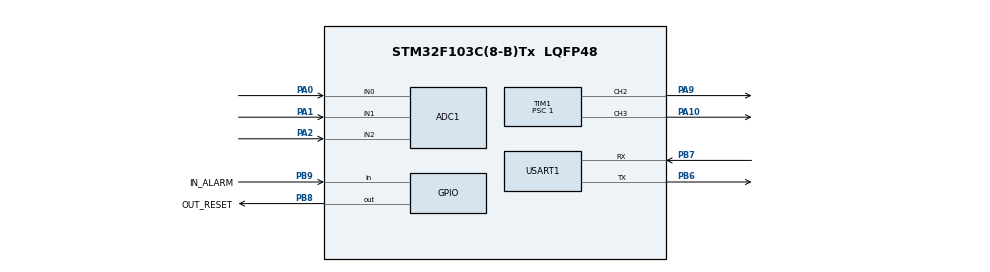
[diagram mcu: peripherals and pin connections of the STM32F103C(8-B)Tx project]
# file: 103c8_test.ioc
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ADC1.Channel-0\#ChannelRegularConversion=ADC_CHANNEL_0
ADC1.Channel-1\#ChannelRegularConversion=ADC_CHANNEL_1
ADC1.Channel-2\#ChannelRegularConversion=ADC_CHANNEL_2
ADC1.ContinuousConvMode=ENABLE
ADC1.DataAlign=ADC_DATAALIGN_RIGHT
ADC1.DiscontinuousConvMode=DISABLE
ADC1.EnableAnalogWatchDog=false
ADC1.EnableRegularConversion=ENABLE
ADC1.ExternalTrigConv=ADC_SOFTWARE_START
ADC1.InjNumberOfConversion=0
ADC1.NbrOfConversion=3
ADC1.NbrOfConversionFlag=1
ADC1.Rank-0\#ChannelRegularConversion=1
ADC1.Rank-1\#ChannelRegularConversion=2
ADC1.Rank-2\#ChannelRegularConversion=3
ADC1.SamplingTime-0\#ChannelRegularConversion=ADC_SAMPLETIME_239CYCLES_5
ADC1.SamplingTime-1\#ChannelRegularConversion=ADC_SAMPLETIME_239CYCLES_5
ADC1.SamplingTime-2\#ChannelRegularConversion=ADC_SAMPLETIME_239CYCLES_5
ADC1.ScanConvMode=ADC_SCAN_ENABLE
ADC1.master=1
Dma.ADC1.1.Direction=DMA_PERIPH_TO_MEMORY
Dma.ADC1.1.Instance=DMA1_Channel1
Dma.ADC1.1.MemDataAlignment=DMA_MDATAALIGN_WORD
Dma.ADC1.1.MemInc=DMA_MINC_ENABLE
Dma.ADC1.1.Mode=DMA_CIRCULAR
Dma.ADC1.1.PeriphDataAlignment=DMA_PDATAALIGN_WORD
Dma.ADC1.1.PeriphInc=DMA_PINC_DISABLE
Dma.ADC1.1.Priority=DMA_PRIORITY_LOW
Dma.Request0=USART1_RX
Dma.Request1=ADC1
Dma.USART1_RX.0.Direction=DMA_PERIPH_TO_MEMORY
Dma.USART1_RX.0.Instance=DMA1_Channel5
Dma.USART1_RX.0.MemDataAlignment=DMA_MDATAALIGN_BYTE
Dma.USART1_RX.0.MemInc=DMA_MINC_ENABLE
Dma.USART1_RX.0.Mode=DMA_NORMAL
Dma.USART1_RX.0.PeriphDataAlignment=DMA_PDATAALIGN_BYTE
Dma.USART1_RX.0.PeriphInc=DMA_PINC_DISABLE
Dma.USART1_RX.0.Priority=DMA_PRIORITY_LOW
Mcu.Family=STM32F1
Mcu.Name=STM32F103C(8-B)Tx
Mcu.Package=LQFP48
NVIC.ADC1_2_IRQn=true\:0\:0\:false\:false\:true\:true
NVIC.DMA1_Channel1_IRQn=true\:0\:0\:false\:false\:true\:false
NVIC.DMA1_Channel5_IRQn=true\:0\:0\:false\:false\:true\:false
NVIC.PriorityGroup=NVIC_PRIORITYGROUP_4
NVIC.USART1_IRQn=true\:0\:0\:false\:false\:true\:true
PA0-WKUP.Signal=ADCx_IN0
PA1.Signal=ADCx_IN1
PA10.Signal=S_TIM1_CH3
PA13.Mode=Serial_Wire
PA13.Signal=SYS_JTMS-SWDIO
PA14.Mode=Serial_Wire
PA14.Signal=SYS_JTCK-SWCLK
PA2.Signal=ADCx_IN2
PA9.Signal=S_TIM1_CH2
PB6.Mode=Asynchronous
PB6.Signal=USART1_TX
PB7.Mode=Asynchronous
PB7.Signal=USART1_RX
PB8.GPIO_Label=OUT_RESET
PB8.Signal=GPIO_Output
PB9.GPIO_Label=IN_ALARM
PB9.Signal=GPIO_Input
ProjectManager.HeapSize=0x200
ProjectManager.StackSize=0x400
ProjectManager.TargetToolchain=TrueSTUDIO
RCC.APB1Freq_Value=8000000
RCC.APB2Freq_Value=8000000
SH.ADCx_IN0.0=ADC1_IN0,IN0
SH.ADCx_IN1.0=ADC1_IN1,IN1
SH.ADCx_IN2.0=ADC1_IN2,IN2
SH.S_TIM1_CH2.0=TIM1_CH2,PWM Generation2 CH2
SH.S_TIM1_CH3.0=TIM1_CH3,PWM Generation3 CH3
TIM1.Channel-PWM\ Generation2\ CH2=TIM_CHANNEL_2
TIM1.Channel-PWM\ Generation3\ CH3=TIM_CHANNEL_3
TIM1.Period=399
TIM1.Prescaler=1
USART1.VirtualMode=VM_ASYNC
VP_TIM1_VS_ClockSourceINT.Mode=Internal
board=custom

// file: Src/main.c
/**
  ******************************************************************************
  * @file           : main.c
  * @brief          : Main program body
  ******************************************************************************
  ** This notice applies to any and all portions of this file
  * that are not between comment pairs USER CODE BEGIN and
  * USER CODE END. Other portions of this file, whether
  * inserted by the user or by software development tools
  * are owned by their respective copyright owners.
  *
  * COPYRIGHT(c) 2020 STMicroelectronics
  *
  * Redistribution and use in source and binary forms, with or without modification,
  * are permitted provided that the following conditions are met:
  *   1. Redistributions of source code must retain the above copyright notice,
  *      this list of conditions and the following disclaimer.
  *   2. Redistributions in binary form must reproduce the above copyright notice,
  *      this list of conditions and the following disclaimer in the documentation
  *      and/or other materials provided with the distribution.
  *   3. Neither the name of STMicroelectronics nor the names of its contributors
  *      may be used to endorse or promote products derived from this software
  *      without specific prior written permission.
  *
  * THIS SOFTWARE IS PROVIDED BY THE COPYRIGHT HOLDERS AND CONTRIBUTORS "AS IS"
  * AND ANY EXPRESS OR IMPLIED WARRANTIES, INCLUDING, BUT NOT LIMITED TO, THE
  * IMPLIED WARRANTIES OF MERCHANTABILITY AND FITNESS FOR A PARTICULAR PURPOSE ARE
  * DISCLAIMED. IN NO EVENT SHALL THE COPYRIGHT HOLDER OR CONTRIBUTORS BE LIABLE
  * FOR ANY DIRECT, INDIRECT, INCIDENTAL, SPECIAL, EXEMPLARY, OR CONSEQUENTIAL
  * DAMAGES (INCLUDING, BUT NOT LIMITED TO, PROCUREMENT OF SUBSTITUTE GOODS OR
  * SERVICES; LOSS OF USE, DATA, OR PROFITS; OR BUSINESS INTERRUPTION) HOWEVER
  * CAUSED AND ON ANY THEORY OF LIABILITY, WHETHER IN CONTRACT, STRICT LIABILITY,
  * OR TORT (INCLUDING NEGLIGENCE OR OTHERWISE) ARISING IN ANY WAY OUT OF THE USE
  * OF THIS SOFTWARE, EVEN IF ADVISED OF THE POSSIBILITY OF SUCH DAMAGE.
  *
  ******************************************************************************
  */
#include "main.h"
#include "stm32f1xx_hal.h"

ADC_HandleTypeDef hadc1;
DMA_HandleTypeDef hdma_adc1;

TIM_HandleTypeDef htim1;

UART_HandleTypeDef huart1;
DMA_HandleTypeDef hdma_usart1_rx;

/* USER CODE BEGIN PV */
/* Private variables ---------------------------------------------------------*/

/* USER CODE END PV */

uint8_t buffer[20];
uint8_t bufferA[20];
uint32_t adc_read[3];
uint32_t buffer1[3];
uint8_t buff[3][20];
char _buf[10];
char sender_buffer[30];

uint32_t adc_read0=0;
uint32_t adc_read1=0;
uint32_t adc_read2=0;

uint8_t freq =0;
uint16_t period=0;

uint8_t current = 0;
uint8_t _pwm=0;

uint16_t read0=0;
char *ptr;

uint32_t timer=0,timer1=0,timer2=0;

uint8_t flag=0,flag1=1,alarm_flag=0,link=0;

uint8_t _c=0,_f=0, _r=0;

uint16_t main_current=0,mos1_current=0,mos2_current=0;

#define MOSFET_CURRENT 120U
/* USER CODE END PV */

void sendData(void);
long map(long , long , long , long , long );
void SystemClock_Config(void);
static void MX_GPIO_Init(void);
static void MX_DMA_Init(void);
static void MX_ADC1_Init(void);
static void MX_TIM1_Init(void);
static void MX_USART1_UART_Init(void);

void HAL_TIM_MspPostInit(TIM_HandleTypeDef *htim);

/* USER CODE BEGIN PFP */
/* Private function prototypes -----------------------------------------------*/
void HAL_ADC_ConvCpltCallback(ADC_HandleTypeDef* hadc)
{
	adc_read0 = buffer1[0];
	adc_read1 = buffer1[1];
	adc_read2 = buffer1[2];
}

void HAL_UART_RxCpltCallback(UART_HandleTypeDef *huart)
{
	HAL_UART_Receive_DMA(&huart1,bufferA,18);
	//read0 = strtol(bufferA,&ptr,10);
	//period = read0;

}
/* USER CODE END PFP */

int main(void)
{

  /* MCU Configuration----------------------------------------------------------*/

  /* Reset of all peripherals, Initializes the Flash interface and the Systick. */
  HAL_Init();

  /* Configure the system clock */
  SystemClock_Config();

  /* Initialize all configured peripherals */
  MX_GPIO_Init();
  MX_DMA_Init();
  MX_ADC1_Init();
  MX_TIM1_Init();
  MX_USART1_UART_Init();
  /* USER CODE BEGIN 2 */

  HAL_ADC_Start_DMA(&hadc1,buffer1,3);

  HAL_TIM_PWM_Start(&htim1,TIM_CHANNEL_3);
  HAL_TIM_PWM_Start(&htim1,TIM_CHANNEL_2);

  HAL_UART_Receive_DMA(&huart1,bufferA,18);
  //TIM1->CCR2 = ((100-50)*399)/100;
  //TIM1->CCR3 = ((100-70)*399)/100;

  _pwm=50;
  period = 50;

  timer = HAL_GetTick();
  timer1 = timer;
  timer2 = timer;

  while (1)
  {

	if( (HAL_GetTick() - timer) >= period  && flag==1)
	{
		TIM1->CCR3 = (0*399)/100;
		TIM1->CCR2 = (_pwm*399)/100;
		timer = HAL_GetTick();
		flag=0;
	}
	if( (HAL_GetTick() - timer) >= period  && flag==0)
	{
		TIM1->CCR2 = (0*399)/100;
		TIM1->CCR3 = (_pwm*399)/100;
		timer = HAL_GetTick();
		flag=1;

			/*uint32_t ee = HAL_GetTick();
			sprintf(buff[0],"%lu",(ee-timer2));
			timer2 = HAL_GetTick();
			HAL_UART_Transmit(&huart1,buff[0],6,100);
			HAL_UART_Transmit(&huart1,"\r\n",3,100);*/
	}

	if( (HAL_GetTick() - timer1) >= 250 )
	{
		timer1 = HAL_GetTick();

		if( HAL_GPIO_ReadPin(IN_ALARM_GPIO_Port,IN_ALARM_Pin) == 0) alarm_flag &= 0xFE;
		if( HAL_GPIO_ReadPin(IN_ALARM_GPIO_Port,IN_ALARM_Pin) == 1) alarm_flag |= 0x01;

		main_current = adc_read0*3300/4096;
		mos1_current = adc_read1*3300/4096;
		mos2_current = adc_read2*3300/4096;

		if( mos1_current>120)
		{
			alarm_flag |= 0x04;
		}
		else alarm_flag &= 0xFB;

		if(mos2_current>120)
		{
			alarm_flag |= 0x10;
		}
		else alarm_flag &= 0xEF;

		//sprintf(buff,"%d",period);
		_buf[0] = bufferA[2];
		_buf[1] = bufferA[3];
		_buf[2] = bufferA[4];
		_c = strtol(_buf,&ptr,10);
		if(link == 1 && alarm_flag == 0)_pwm = map(_c ,0 ,100 ,0 ,47 );
		else _pwm =0;

		_buf[0] = bufferA[8];
		_buf[1] = bufferA[9];
		_buf[2] = bufferA[10];
		_f = strtol(_buf,&ptr,10);
		period = 1000/_f;
		if(period < 10)period = 10;
		if(period > 500)period = 500;

		//HAL_UART_Transmit(&huart1,"andy abreu reyes",17,100);

		sendData();

		if( bufferA[11] == '_' && bufferA[12] == 'R' && bufferA[13] == ':' )
		{
			if( bufferA[14] == '1' ) _r=1;
			if( bufferA[14] == '0' ) _r=0;
			if( bufferA[15] == '2' ) link=1;
			else if( bufferA[15] != '2' ) link=0;

		}

		if( _r == 1 && flag1==1)
		{
			HAL_GPIO_WritePin(OUT_RESET_GPIO_Port,OUT_RESET_Pin,1);
			flag1=0;
			continue;
		}
		if( _r == 1 && flag1==0)
		{
			HAL_GPIO_WritePin(OUT_RESET_GPIO_Port,OUT_RESET_Pin,0);
			flag1=1;
			_r=0;
			bufferA[14]='0';
			continue;
		}
	}
	//HAL_UART_Transmit(&huart1,buff[0],6,100);
	//HAL_UART_Transmit(&huart1,"\r\n",3,100);
	  //HAL_Delay(1000);

  }

}

long map(long x, long in_min, long in_max, long out_min, long out_max)
{
  return (x - in_min) * (out_max - out_min) / (in_max - in_min) + out_min;
}

void sendData(void)
{

	sender_buffer[0] = 'C';
	sender_buffer[1] = ':';

	sender_buffer[2] = main_current/100 +48;
	sender_buffer[3] = (main_current%100)/10 +48;
	sender_buffer[4] = main_current%10 +48;

	sender_buffer[5] = '_';
	sender_buffer[6] = 'M';
	sender_buffer[7] = '1';
	sender_buffer[8] = ':';

	sender_buffer[9] = mos1_current/100 +48;
	sender_buffer[10] = (mos1_current%100)/10 +48;
	sender_buffer[11] = mos1_current%10 +48;

	sender_buffer[12] = '_';
	sender_buffer[13] = 'M';
	sender_buffer[14] = '2';
	sender_buffer[15] = ':';

	sender_buffer[16] = mos2_current/100 +48;
	sender_buffer[17] = (mos2_current%100)/10 +48;
	sender_buffer[18] = mos2_current%10 +48;

	sender_buffer[19] = '_';
	sender_buffer[20] = 'A';
	sender_buffer[21] = ':';

	sender_buffer[22] = alarm_flag/100 +48;
	sender_buffer[23] = (alarm_flag%100)/10 +48;
	sender_buffer[24] = alarm_flag%10 +48;

	  HAL_UART_Transmit(&huart1,&sender_buffer,25,100);
	  HAL_UART_Transmit(&huart1,"\r\n",3,100);

}
void SystemClock_Config(void)
{

  RCC_OscInitTypeDef RCC_OscInitStruct;
  RCC_ClkInitTypeDef RCC_ClkInitStruct;
  RCC_PeriphCLKInitTypeDef PeriphClkInit;

    /**Initializes the CPU, AHB and APB busses clocks
    */
  RCC_OscInitStruct.OscillatorType = RCC_OSCILLATORTYPE_HSI;
  RCC_OscInitStruct.HSIState = RCC_HSI_ON;
  RCC_OscInitStruct.HSICalibrationValue = 16;
  RCC_OscInitStruct.PLL.PLLState = RCC_PLL_NONE;
  if (HAL_RCC_OscConfig(&RCC_OscInitStruct) != HAL_OK)
  {
    _Error_Handler(__FILE__, __LINE__);
  }

    /**Initializes the CPU, AHB and APB busses clocks
    */
  RCC_ClkInitStruct.ClockType = RCC_CLOCKTYPE_HCLK|RCC_CLOCKTYPE_SYSCLK
                              |RCC_CLOCKTYPE_PCLK1|RCC_CLOCKTYPE_PCLK2;
  RCC_ClkInitStruct.SYSCLKSource = RCC_SYSCLKSOURCE_HSI;
  RCC_ClkInitStruct.AHBCLKDivider = RCC_SYSCLK_DIV1;
  RCC_ClkInitStruct.APB1CLKDivider = RCC_HCLK_DIV1;
  RCC_ClkInitStruct.APB2CLKDivider = RCC_HCLK_DIV1;

  if (HAL_RCC_ClockConfig(&RCC_ClkInitStruct, FLASH_LATENCY_0) != HAL_OK)
  {
    _Error_Handler(__FILE__, __LINE__);
  }

  PeriphClkInit.PeriphClockSelection = RCC_PERIPHCLK_ADC;
  PeriphClkInit.AdcClockSelection = RCC_ADCPCLK2_DIV2;
  if (HAL_RCCEx_PeriphCLKConfig(&PeriphClkInit) != HAL_OK)
  {
    _Error_Handler(__FILE__, __LINE__);
  }

    /**Configure the Systick interrupt time
    */
  HAL_SYSTICK_Config(HAL_RCC_GetHCLKFreq()/1000);

    /**Configure the Systick
    */
  HAL_SYSTICK_CLKSourceConfig(SYSTICK_CLKSOURCE_HCLK);

  /* SysTick_IRQn interrupt configuration */
  HAL_NVIC_SetPriority(SysTick_IRQn, 0, 0);
}

/* ADC1 init function */
static void MX_ADC1_Init(void)
{

  ADC_ChannelConfTypeDef sConfig;

    /**Common config
    */
  hadc1.Instance = ADC1;
  hadc1.Init.ScanConvMode = ADC_SCAN_ENABLE;
  hadc1.Init.ContinuousConvMode = ENABLE;
  hadc1.Init.DiscontinuousConvMode = DISABLE;
  hadc1.Init.ExternalTrigConv = ADC_SOFTWARE_START;
  hadc1.Init.DataAlign = ADC_DATAALIGN_RIGHT;
  hadc1.Init.NbrOfConversion = 3;
  if (HAL_ADC_Init(&hadc1) != HAL_OK)
  {
    _Error_Handler(__FILE__, __LINE__);
  }

    /**Configure Regular Channel
    */
  sConfig.Channel = ADC_CHANNEL_0;
  sConfig.Rank = ADC_REGULAR_RANK_1;
  sConfig.SamplingTime = ADC_SAMPLETIME_239CYCLES_5;
  if (HAL_ADC_ConfigChannel(&hadc1, &sConfig) != HAL_OK)
  {
    _Error_Handler(__FILE__, __LINE__);
  }

    /**Configure Regular Channel
    */
  sConfig.Channel = ADC_CHANNEL_1;
  sConfig.Rank = ADC_REGULAR_RANK_2;
  if (HAL_ADC_ConfigChannel(&hadc1, &sConfig) != HAL_OK)
  {
    _Error_Handler(__FILE__, __LINE__);
  }

    /**Configure Regular Channel
    */
  sConfig.Channel = ADC_CHANNEL_2;
  sConfig.Rank = ADC_REGULAR_RANK_3;
  if (HAL_ADC_ConfigChannel(&hadc1, &sConfig) != HAL_OK)
  {
    _Error_Handler(__FILE__, __LINE__);
  }

}

/* TIM1 init function */
static void MX_TIM1_Init(void)
{

  TIM_ClockConfigTypeDef sClockSourceConfig;
  TIM_MasterConfigTypeDef sMasterConfig;
  TIM_OC_InitTypeDef sConfigOC;
  TIM_BreakDeadTimeConfigTypeDef sBreakDeadTimeConfig;

  htim1.Instance = TIM1;
  htim1.Init.Prescaler = 1;
  htim1.Init.CounterMode = TIM_COUNTERMODE_UP;
  htim1.Init.Period = 399;
  htim1.Init.ClockDivision = TIM_CLOCKDIVISION_DIV1;
  htim1.Init.RepetitionCounter = 0;
  htim1.Init.AutoReloadPreload = TIM_AUTORELOAD_PRELOAD_DISABLE;
  if (HAL_TIM_Base_Init(&htim1) != HAL_OK)
  {
    _Error_Handler(__FILE__, __LINE__);
  }

  sClockSourceConfig.ClockSource = TIM_CLOCKSOURCE_INTERNAL;
  if (HAL_TIM_ConfigClockSource(&htim1, &sClockSourceConfig) != HAL_OK)
  {
    _Error_Handler(__FILE__, __LINE__);
  }

  if (HAL_TIM_PWM_Init(&htim1) != HAL_OK)
  {
    _Error_Handler(__FILE__, __LINE__);
  }

  sMasterConfig.MasterOutputTrigger = TIM_TRGO_RESET;
  sMasterConfig.MasterSlaveMode = TIM_MASTERSLAVEMODE_DISABLE;
  if (HAL_TIMEx_MasterConfigSynchronization(&htim1, &sMasterConfig) != HAL_OK)
  {
    _Error_Handler(__FILE__, __LINE__);
  }

  sConfigOC.OCMode = TIM_OCMODE_PWM1;
  sConfigOC.Pulse = 0;
  sConfigOC.OCPolarity = TIM_OCPOLARITY_HIGH;
  sConfigOC.OCNPolarity = TIM_OCNPOLARITY_HIGH;
  sConfigOC.OCFastMode = TIM_OCFAST_DISABLE;
  sConfigOC.OCIdleState = TIM_OCIDLESTATE_RESET;
  sConfigOC.OCNIdleState = TIM_OCNIDLESTATE_RESET;
  if (HAL_TIM_PWM_ConfigChannel(&htim1, &sConfigOC, TIM_CHANNEL_2) != HAL_OK)
  {
    _Error_Handler(__FILE__, __LINE__);
  }

  if (HAL_TIM_PWM_ConfigChannel(&htim1, &sConfigOC, TIM_CHANNEL_3) != HAL_OK)
  {
    _Error_Handler(__FILE__, __LINE__);
  }

  sBreakDeadTimeConfig.OffStateRunMode = TIM_OSSR_DISABLE;
  sBreakDeadTimeConfig.OffStateIDLEMode = TIM_OSSI_DISABLE;
  sBreakDeadTimeConfig.LockLevel = TIM_LOCKLEVEL_OFF;
  sBreakDeadTimeConfig.DeadTime = 0;
  sBreakDeadTimeConfig.BreakState = TIM_BREAK_DISABLE;
  sBreakDeadTimeConfig.BreakPolarity = TIM_BREAKPOLARITY_HIGH;
  sBreakDeadTimeConfig.AutomaticOutput = TIM_AUTOMATICOUTPUT_DISABLE;
  if (HAL_TIMEx_ConfigBreakDeadTime(&htim1, &sBreakDeadTimeConfig) != HAL_OK)
  {
    _Error_Handler(__FILE__, __LINE__);
  }

  HAL_TIM_MspPostInit(&htim1);

}

/* USART1 init function */
static void MX_USART1_UART_Init(void)
{

  huart1.Instance = USART1;
  huart1.Init.BaudRate = 115200;
  huart1.Init.WordLength = UART_WORDLENGTH_8B;
  huart1.Init.StopBits = UART_STOPBITS_1;
  huart1.Init.Parity = UART_PARITY_NONE;
  huart1.Init.Mode = UART_MODE_TX_RX;
  huart1.Init.HwFlowCtl = UART_HWCONTROL_NONE;
  huart1.Init.OverSampling = UART_OVERSAMPLING_16;
  if (HAL_UART_Init(&huart1) != HAL_OK)
  {
    _Error_Handler(__FILE__, __LINE__);
  }

}

static void MX_DMA_Init(void)
{
  /* DMA controller clock enable */
  __HAL_RCC_DMA1_CLK_ENABLE();

  /* DMA interrupt init */
  /* DMA1_Channel1_IRQn interrupt configuration */
  HAL_NVIC_SetPriority(DMA1_Channel1_IRQn, 0, 0);
  HAL_NVIC_EnableIRQ(DMA1_Channel1_IRQn);
  /* DMA1_Channel5_IRQn interrupt configuration */
  HAL_NVIC_SetPriority(DMA1_Channel5_IRQn, 0, 0);
  HAL_NVIC_EnableIRQ(DMA1_Channel5_IRQn);

}

/** Configure pins as
        * Analog
        * Input
        * Output
        * EVENT_OUT
        * EXTI
*/
static void MX_GPIO_Init(void)
{

  GPIO_InitTypeDef GPIO_InitStruct;

  /* GPIO Ports Clock Enable */
  __HAL_RCC_GPIOA_CLK_ENABLE();
  __HAL_RCC_GPIOB_CLK_ENABLE();

  /*Configure GPIO pin Output Level */
  HAL_GPIO_WritePin(OUT_RESET_GPIO_Port, OUT_RESET_Pin, GPIO_PIN_RESET);

  /*Configure GPIO pin : OUT_RESET_Pin */
  GPIO_InitStruct.Pin = OUT_RESET_Pin;
  GPIO_InitStruct.Mode = GPIO_MODE_OUTPUT_PP;
  GPIO_InitStruct.Pull = GPIO_NOPULL;
  GPIO_InitStruct.Speed = GPIO_SPEED_FREQ_LOW;
  HAL_GPIO_Init(OUT_RESET_GPIO_Port, &GPIO_InitStruct);

  /*Configure GPIO pin : IN_ALARM_Pin */
  GPIO_InitStruct.Pin = IN_ALARM_Pin;
  GPIO_InitStruct.Mode = GPIO_MODE_INPUT;
  GPIO_InitStruct.Pull = GPIO_NOPULL;
  HAL_GPIO_Init(IN_ALARM_GPIO_Port, &GPIO_InitStruct);

}

void _Error_Handler(char *file, int line)
{
  while(1)
  {
  }
}

/************************ (C) COPYRIGHT STMicroelectronics *****END OF FILE****/
